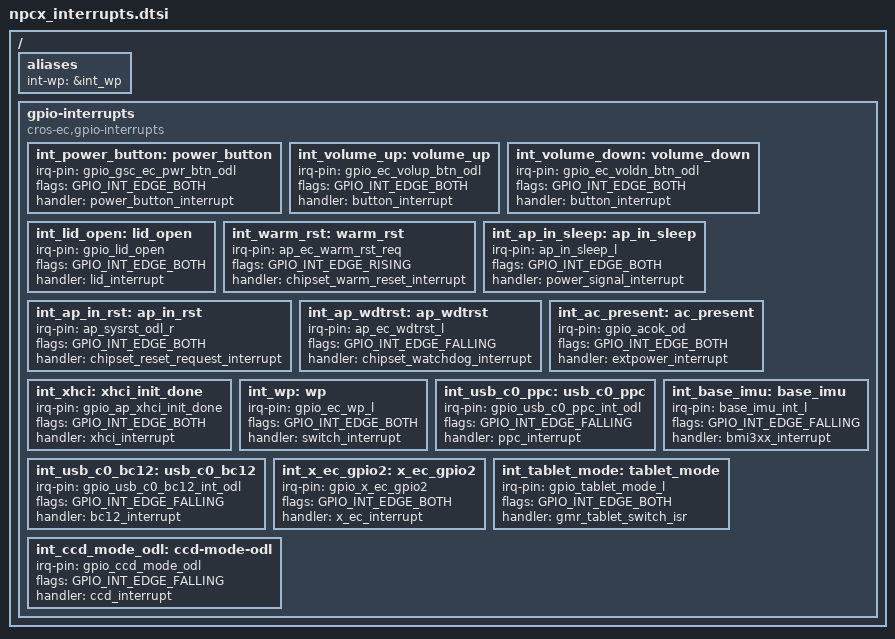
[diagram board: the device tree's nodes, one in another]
/* Copyright 2022 The ChromiumOS Authors
 * Use of this source code is governed by a BSD-style license that can be
 * found in the LICENSE file.
 */

/*
 * Kingler and Steelix use the same dts, take care of this when modify it.
 */

/ {
	aliases {
		int-wp = &int_wp;
	};

	gpio-interrupts {
		compatible = "cros-ec,gpio-interrupts";

		int_power_button: power_button {
			irq-pin = <&gpio_gsc_ec_pwr_btn_odl>;
			flags = <GPIO_INT_EDGE_BOTH>;
			handler = "power_button_interrupt";
		};
		int_volume_up: volume_up {
			irq-pin = <&gpio_ec_volup_btn_odl>;
			flags = <GPIO_INT_EDGE_BOTH>;
			handler = "button_interrupt";
		};
		int_volume_down: volume_down {
			irq-pin = <&gpio_ec_voldn_btn_odl>;
			flags = <GPIO_INT_EDGE_BOTH>;
			handler = "button_interrupt";
		};
		int_lid_open: lid_open {
			irq-pin = <&gpio_lid_open>;
			flags = <GPIO_INT_EDGE_BOTH>;
			handler = "lid_interrupt";
		};
		int_warm_rst: warm_rst {
			irq-pin = <&ap_ec_warm_rst_req>;
			flags = <GPIO_INT_EDGE_RISING>;
			handler = "chipset_warm_reset_interrupt";
		};
		int_ap_in_sleep: ap_in_sleep {
			irq-pin = <&ap_in_sleep_l>;
			flags = <GPIO_INT_EDGE_BOTH>;
			handler = "power_signal_interrupt";
		};
		int_ap_in_rst: ap_in_rst {
			irq-pin = <&ap_sysrst_odl_r>;
			flags = <GPIO_INT_EDGE_BOTH>;
			handler = "chipset_reset_request_interrupt";
		};
		int_ap_wdtrst: ap_wdtrst {
			irq-pin = <&ap_ec_wdtrst_l>;
			flags = <GPIO_INT_EDGE_FALLING>;
			handler = "chipset_watchdog_interrupt";
		};
		int_ac_present: ac_present {
			irq-pin = <&gpio_acok_od>;
			flags = <GPIO_INT_EDGE_BOTH>;
			handler = "extpower_interrupt";
		};
		int_xhci: xhci_init_done {
			irq-pin = <&gpio_ap_xhci_init_done>;
			flags = <GPIO_INT_EDGE_BOTH>;
			handler = "xhci_interrupt";
		};
		int_wp: wp {
			irq-pin = <&gpio_ec_wp_l>;
			flags = <GPIO_INT_EDGE_BOTH>;
			handler = "switch_interrupt";
		};
		int_usb_c0_ppc: usb_c0_ppc {
			irq-pin = <&gpio_usb_c0_ppc_int_odl>;
			flags = <GPIO_INT_EDGE_FALLING>;
			handler = "ppc_interrupt";
		};
		int_usb_c0_bc12: usb_c0_bc12 {
			irq-pin = <&gpio_usb_c0_bc12_int_odl>;
			flags = <GPIO_INT_EDGE_FALLING>;
			handler = "bc12_interrupt";
		};
		int_x_ec_gpio2: x_ec_gpio2 {
			irq-pin = <&gpio_x_ec_gpio2>;
			flags = <GPIO_INT_EDGE_BOTH>;
			handler = "x_ec_interrupt";
		};
		int_base_imu: base_imu {
			irq-pin = <&base_imu_int_l>;
			flags = <GPIO_INT_EDGE_FALLING>;
			handler = "bmi3xx_interrupt";
		};
		int_tablet_mode: tablet_mode {
			irq-pin = <&gpio_tablet_mode_l>;
			flags = <GPIO_INT_EDGE_BOTH>;
			handler = "gmr_tablet_switch_isr";
		};
		int_ccd_mode_odl: ccd-mode-odl {
			irq-pin = <&gpio_ccd_mode_odl>;
			flags = <GPIO_INT_EDGE_FALLING>;
			handler = "ccd_interrupt";
		};
	};
};
